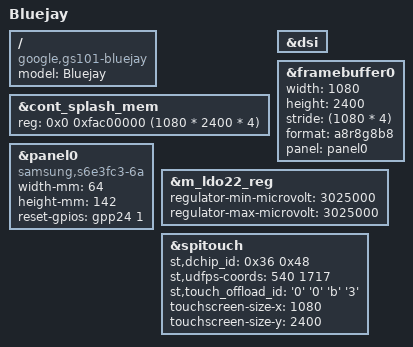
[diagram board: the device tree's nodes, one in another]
// SPDX-License-Identifier: GPL-2.0-only
/*
 * Bluejay Device Tree
 *
 * Copyright 2021-2023 Google LLC
 */

/dts-v1/;

#include "gs101-pixel-common.dtsi"

/ {
	model = "Bluejay";
	compatible = "google,gs101-bluejay", "google,gs101";
};

&cont_splash_mem {
	reg = <0x0 0xfac00000 (1080 * 2400 * 4)>;
	status = "okay";
};

&dsi {
	status = "okay";
};

&panel0 {
	status = "okay";
	compatible = "samsung,s6e3fc3-6a";
	width-mm = <64>;
	height-mm = <142>;
	reset-gpios = <&gpp24 1 GPIO_ACTIVE_HIGH>;
};

&framebuffer0 {
	width = <1080>;
	height = <2400>;
	stride = <(1080 * 4)>;
	format = "a8r8g8b8";
	status = "okay";

	panel = <&panel0>;
};

&m_ldo22_reg {
	regulator-min-microvolt = <3025000>;
	regulator-max-microvolt = <3025000>;
};

&spitouch {
	st,dchip_id = /bits/ 8 <0x36 0x48>;
	st,udfps-coords = <540 1717>;
	st,touch_offload_id = /bits/ 8 <'0' '0' 'b' '3'>;

	touchscreen-size-x = <1080>;
	touchscreen-size-y = <2400>;
};
